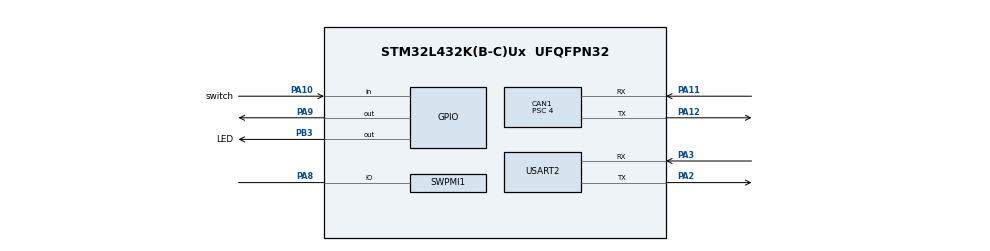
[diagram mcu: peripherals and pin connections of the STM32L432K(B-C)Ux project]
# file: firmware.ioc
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CAN1.BS1=CAN_BS1_6TQ
CAN1.BS2=CAN_BS2_3TQ
CAN1.CalculateBaudRate=100000
CAN1.CalculateTimeBit=10000
CAN1.CalculateTimeQuantum=1000.0
CAN1.Prescaler=4
Mcu.Family=STM32L4
Mcu.Name=STM32L432K(B-C)Ux
Mcu.Package=UFQFPN32
NVIC.CAN1_RX0_IRQn=true\:0\:0\:false\:false\:true\:true\:true\:true
NVIC.CAN1_RX1_IRQn=true\:0\:0\:false\:false\:true\:true\:true\:true
NVIC.PriorityGroup=NVIC_PRIORITYGROUP_4
NVIC.USART2_IRQn=true\:0\:0\:false\:false\:true\:true\:true\:true
PA10.GPIO_Label=switch
PA10.Signal=GPIO_Input
PA11.Mode=CAN_Activate
PA11.Signal=CAN1_RX
PA12.Mode=CAN_Activate
PA12.Signal=CAN1_TX
PA13\ (JTMS-SWDIO).Signal=SYS_JTMS-SWDIO
PA14\ (JTCK-SWCLK).Signal=SYS_JTCK-SWCLK
PA2.Mode=Asynchronous
PA2.Signal=USART2_TX
PA3.Mode=Asynchronous
PA3.Signal=USART2_RX
PA8.Mode=fullDuplex
PA8.Signal=SWPMI1_IO
PA9.Signal=GPIO_Output
PB3\ (JTDO-TRACESWO).GPIO_Label=LED
PB3\ (JTDO-TRACESWO).Signal=GPIO_Output
PC14-OSC32_IN\ (PC14).Mode=LSE-External-Oscillator
PC14-OSC32_IN\ (PC14).Signal=RCC_OSC32_IN
PC15-OSC32_OUT\ (PC15).Mode=LSE-External-Oscillator
PC15-OSC32_OUT\ (PC15).Signal=RCC_OSC32_OUT
ProjectManager.HeapSize=0x200
ProjectManager.StackSize=0x400
ProjectManager.TargetToolchain=Makefile
RCC.HSE_VALUE=8000000
RCC.HSI48_VALUE=48000000
RCC.HSI_VALUE=16000000
RCC.MSI_VALUE=4000000
RCC.VCOOutputFreq_Value=32000000
USART2.VirtualMode-Asynchronous=VM_ASYNC
board=custom

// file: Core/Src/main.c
/* USER CODE BEGIN Header */
/**
  ******************************************************************************
  * @file           : main.c
  * @brief          : Main program body
  ******************************************************************************
  * @attention
  *
  * Copyright (c) 2025 STMicroelectronics.
  * All rights reserved.
  *
  * This software is licensed under terms that can be found in the LICENSE file
  * in the root directory of this software component.
  * If no LICENSE file comes with this software, it is provided AS-IS.
  *
  ******************************************************************************
  */
/* USER CODE END Header */
#include "main.h"
#include "can.h"
#include "swpmi.h"
#include "usart.h"
#include "gpio.h"

/* USER CODE BEGIN Includes */
#include "mainpp.h"
#include <stdio.h>
#include <string.h>
/* USER CODE END Includes */

void SystemClock_Config(void);

int main(void)
{

  /* USER CODE BEGIN 1 */
  setbuf(stdout, NULL);
  /* USER CODE END 1 */

  /* MCU Configuration--------------------------------------------------------*/

  /* Reset of all peripherals, Initializes the Flash interface and the Systick. */
  HAL_Init();

  /* Configure the system clock */
  SystemClock_Config();

  /* Initialize all configured peripherals */
  MX_GPIO_Init();
  MX_SWPMI1_Init();
  MX_CAN1_Init();
  MX_USART2_UART_Init();
  /* USER CODE BEGIN 2 */
  mainsetup();
  /* USER CODE END 2 */

  /* Infinite loop */
  /* USER CODE BEGIN WHILE */
  while (1)
  {
    maintask();
    /* USER CODE END WHILE */

  }
}

void SystemClock_Config(void)
{
  RCC_OscInitTypeDef RCC_OscInitStruct = {0};
  RCC_ClkInitTypeDef RCC_ClkInitStruct = {0};

  /** Configure the main internal regulator output voltage
  */
  if (HAL_PWREx_ControlVoltageScaling(PWR_REGULATOR_VOLTAGE_SCALE1) != HAL_OK)
  {
    Error_Handler();
  }

  /** Configure LSE Drive Capability
  */
  HAL_PWR_EnableBkUpAccess();
  __HAL_RCC_LSEDRIVE_CONFIG(RCC_LSEDRIVE_LOW);

  /** Initializes the RCC Oscillators according to the specified parameters
  * in the RCC_OscInitTypeDef structure.
  */
  RCC_OscInitStruct.OscillatorType = RCC_OSCILLATORTYPE_LSE|RCC_OSCILLATORTYPE_MSI;
  RCC_OscInitStruct.LSEState = RCC_LSE_ON;
  RCC_OscInitStruct.MSIState = RCC_MSI_ON;
  RCC_OscInitStruct.MSICalibrationValue = 0;
  RCC_OscInitStruct.MSIClockRange = RCC_MSIRANGE_6;
  RCC_OscInitStruct.PLL.PLLState = RCC_PLL_NONE;
  if (HAL_RCC_OscConfig(&RCC_OscInitStruct) != HAL_OK)
  {
    Error_Handler();
  }

  /** Initializes the CPU, AHB and APB buses clocks
  */
  RCC_ClkInitStruct.ClockType = RCC_CLOCKTYPE_HCLK|RCC_CLOCKTYPE_SYSCLK
                              |RCC_CLOCKTYPE_PCLK1|RCC_CLOCKTYPE_PCLK2;
  RCC_ClkInitStruct.SYSCLKSource = RCC_SYSCLKSOURCE_MSI;
  RCC_ClkInitStruct.AHBCLKDivider = RCC_SYSCLK_DIV1;
  RCC_ClkInitStruct.APB1CLKDivider = RCC_HCLK_DIV1;
  RCC_ClkInitStruct.APB2CLKDivider = RCC_HCLK_DIV1;

  if (HAL_RCC_ClockConfig(&RCC_ClkInitStruct, FLASH_LATENCY_0) != HAL_OK)
  {
    Error_Handler();
  }

  /** Enable MSI Auto calibration
  */
  HAL_RCCEx_EnableMSIPLLMode();
}

/* USER CODE BEGIN 4 */
int _write(int file, char *ptr, int len)
{
  HAL_UART_Transmit(&huart2,(uint8_t *)ptr,len,10);
  return len;
}
/* USER CODE END 4 */

void Error_Handler(void)
{
  __disable_irq();
  while (1)
  {
  }
}
